# STM32F303CBT6 register map
File version: 1.0
Registers are 32-bit, access not given, reset 0x0 unless marked. A register's access mark holds for its fields unless they carry their own. Offsets are from the block's base; [hi:lo] are bit positions; {n}, {i} and the like mark numbered series; 'fields as' and 'values as' point back to an identical list.

## TIM15
Base 0x40014000
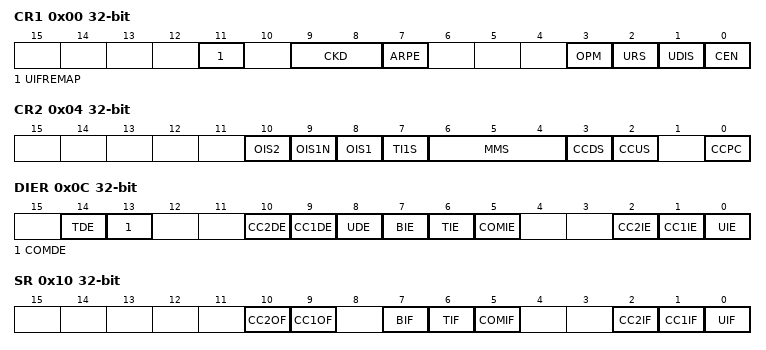
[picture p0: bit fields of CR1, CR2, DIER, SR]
0x00 CR1
  [11] UIFREMAP, [9:8] CKD, [7] ARPE, [3] OPM, [2] URS, [1] UDIS, [0] CEN
0x04 CR2
  [10] OIS2, [9] OIS1N, [8] OIS1, [7] TI1S, [6:4] MMS, [3] CCDS, [2] CCUS, [0] CCPC
0x08 SMCR
  [7] MSM, [6:4] TS, [16:0] SMS
0x0C DIER
  [14] TDE, [13] COMDE, [10] CC2DE, [9] CC1DE, [8] UDE, [7] BIE, [6] TIE, [5] COMIE, [2] CC2IE, [1] CC1IE, [0] UIE
0x10 SR
  [10] CC2OF, [9] CC1OF, [7] BIF, [6] TIF, [5] COMIF, [2] CC2IF, [1] CC1IF, [0] UIF
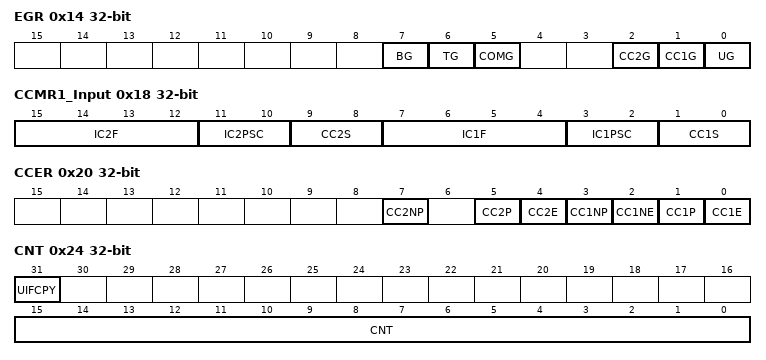
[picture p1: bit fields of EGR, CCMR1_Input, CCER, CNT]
0x14 EGR
  [7] BG, [6] TG, [5] COMG, [2] CC2G, [1] CC1G, [0] UG
0x18 CCMR1_Output
  [24:12] OC2M, [11] OC2PE, [10] OC2FE, [9:8] CC2S, [7] OC1CE, [16:4] OC1M, [3] OC1PE, [2] OC1FE, [1:0] CC1S
0x18 CCMR1_Input
  [15:12] IC2F, [11:10] IC2PSC, [9:8] CC2S, [7:4] IC1F, [3:2] IC1PSC, [1:0] CC1S
0x20 CCER
  [7] CC2NP, [5] CC2P, [4] CC2E, [3] CC1NP, [2] CC1NE, [1] CC1P, [0] CC1E
0x24 CNT
  [31] UIFCPY, [15:0] CNT
0x28 PSC
  [15:0] PSC
0x2C ARR
  [15:0] ARR
0x30 RCR
  [7:0] REP
0x34 CCR1
  [15:0] CCR1
0x38 CCR2
  [15:0] CCR2
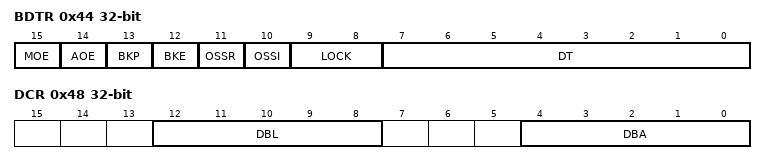
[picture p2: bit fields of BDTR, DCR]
0x44 BDTR
  [15] MOE, [14] AOE, [13] BKP, [12] BKE, [11] OSSR, [10] OSSI, [9:8] LOCK, [7:0] DT
0x48 DCR
  [12:8] DBL, [4:0] DBA
0x4C DMAR
  [15:0] DMAB

## TIM16
Base 0x40014400
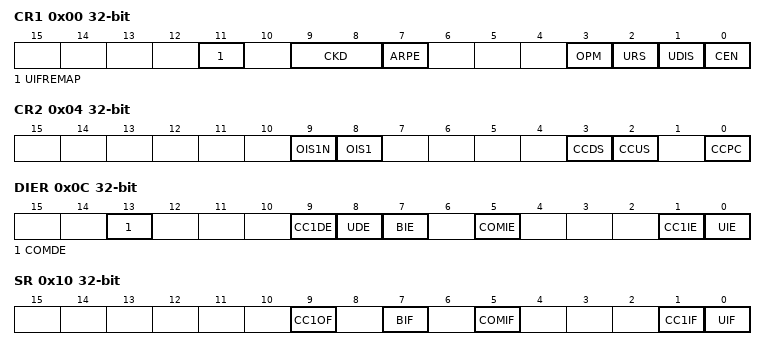
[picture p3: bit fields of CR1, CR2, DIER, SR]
0x00 CR1
  [11] UIFREMAP, [9:8] CKD, [7] ARPE, [3] OPM, [2] URS, [1] UDIS, [0] CEN
0x04 CR2
  [9] OIS1N, [8] OIS1, [3] CCDS, [2] CCUS, [0] CCPC
0x0C DIER
  [13] COMDE, [9] CC1DE, [8] UDE, [7] BIE, [5] COMIE, [1] CC1IE, [0] UIE
0x10 SR
  [9] CC1OF, [7] BIF, [5] COMIF, [1] CC1IF, [0] UIF
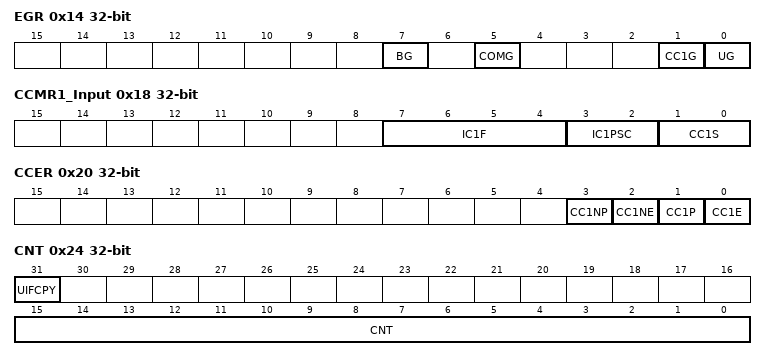
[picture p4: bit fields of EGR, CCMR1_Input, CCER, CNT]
0x14 EGR
  [7] BG, [5] COMG, [1] CC1G, [0] UG
0x18 CCMR1_Output
  [7] OC1CE, [16:4] OC1M, [3] OC1PE, [2] OC1FE, [1:0] CC1S
0x18 CCMR1_Input
  [7:4] IC1F, [3:2] IC1PSC, [1:0] CC1S
0x20 CCER
  [3] CC1NP, [2] CC1NE, [1] CC1P, [0] CC1E
0x24 CNT
  [31] UIFCPY, [15:0] CNT
0x28 PSC
  [15:0] PSC
0x2C ARR
  [15:0] ARR
0x30 RCR
  [7:0] REP
0x34 CCR1
  [15:0] CCR1
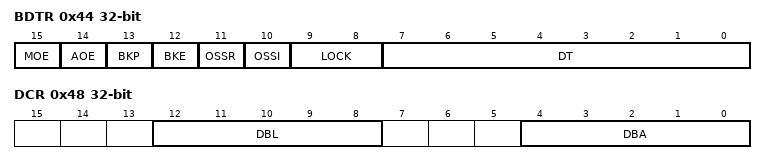
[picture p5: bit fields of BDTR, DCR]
0x44 BDTR
  [15] MOE, [14] AOE, [13] BKP, [12] BKE, [11] OSSR, [10] OSSI, [9:8] LOCK, [7:0] DT
0x48 DCR
  [12:8] DBL, [4:0] DBA
0x4C DMAR
  [15:0] DMAB
0x50 OR
  [1:0] TI1_RMP

## TIM17
Base 0x40014800
Registers as TIM16, without OR.

## DMA1
Base 0x40020000
Same registers: DMA2 0x40020400
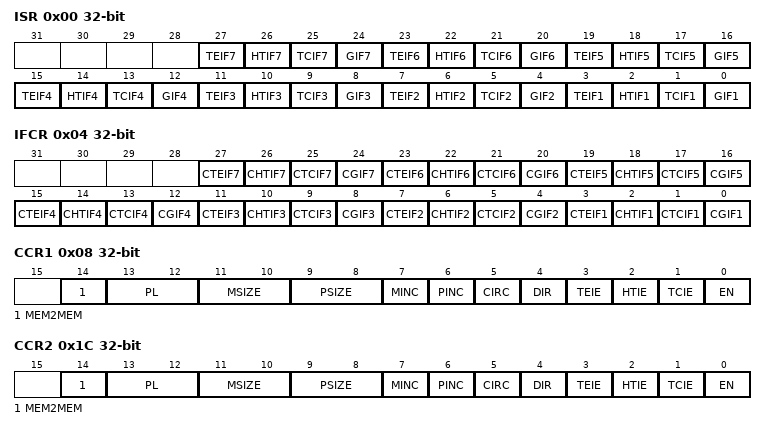
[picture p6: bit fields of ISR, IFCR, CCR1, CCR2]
0x00 ISR
  [4n-1] TEIF{n} (n=1..7), [4n-2] HTIF{n} (n=1..7), [4n-3] TCIF{n} (n=1..7), [4n-4] GIF{n} (n=1..7)
0x04 IFCR
  [4n-1] CTEIF{n} (n=1..7), [4n-2] CHTIF{n} (n=1..7), [4n-3] CTCIF{n} (n=1..7), [4n-4] CGIF{n} (n=1..7)
0x08 CCR1
  [14] MEM2MEM, [13:12] PL, [11:10] MSIZE, [9:8] PSIZE, [7] MINC, [6] PINC, [5] CIRC, [4] DIR, [3] TEIE, [2] HTIE, [1] TCIE, [0] EN
0x0C CNDTR1
  [15:0] NDT
0x10 CPAR1
  [31:0] PA
{0x0+0x14*i} CMAR{i} (i=1..7)
  [31:0] MA
0x1C CCR2
  fields as CCR1
0x20 CNDTR2
  [15:0] NDT
0x24 CPAR2
  [31:0] PA
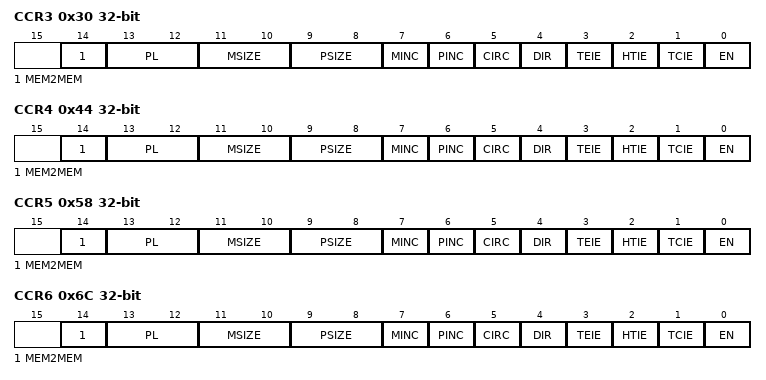
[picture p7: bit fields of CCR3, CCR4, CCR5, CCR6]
0x30 CCR3
  fields as CCR1
0x34 CNDTR3
  [15:0] NDT
0x38 CPAR3
  [31:0] PA
0x44 CCR4
  fields as CCR1
0x48 CNDTR4
  [15:0] NDT
0x4C CPAR4
  [31:0] PA
0x58 CCR5
  fields as CCR1
0x5C CNDTR5
  [15:0] NDT
0x60 CPAR5
  [31:0] PA
0x6C CCR6
  fields as CCR1
0x70 CNDTR6
  [15:0] NDT
0x74 CPAR6
  [31:0] PA
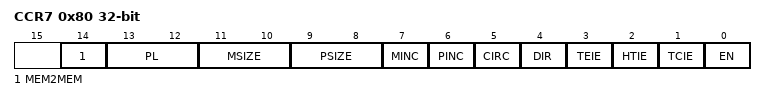
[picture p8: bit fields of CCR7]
0x80 CCR7
  fields as CCR1
0x84 CNDTR7
  [15:0] NDT
0x88 CPAR7
  [31:0] PA

## RCC
Base 0x40021000
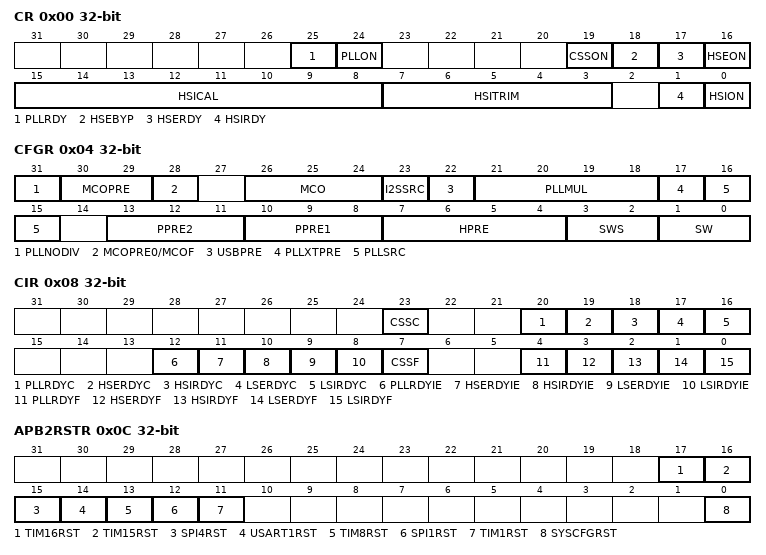
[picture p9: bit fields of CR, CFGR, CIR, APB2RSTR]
0x00 CR
  [25] PLLRDY, [24] PLLON, [19] CSSON, [18] HSEBYP, [17] HSERDY, [16] HSEON, [15:8] HSICAL, [7:3] HSITRIM, [1] HSIRDY, [0] HSION
0x04 CFGR
  [31] PLLNODIV, [30:29] MCOPRE, [28] MCOPRE0/MCOF, [26:24] MCO, [23] I2SSRC, [22] USBPRE, [21:18] PLLMUL, [17] PLLXTPRE, [16:15] PLLSRC, [13:11] PPRE2, [10:8] PPRE1, [7:4] HPRE, [3:2] SWS, [1:0] SW
0x08 CIR
  [23] CSSC, [20] PLLRDYC, [19] HSERDYC, [18] HSIRDYC, [17] LSERDYC, [16] LSIRDYC, [12] PLLRDYIE, [11] HSERDYIE, [10] HSIRDYIE, [9] LSERDYIE, [8] LSIRDYIE, [7] CSSF, [4] PLLRDYF, [3] HSERDYF, [2] HSIRDYF, [1] LSERDYF, [0] LSIRDYF
0x0C APB2RSTR
  [17] TIM16RST, [16] TIM15RST, [15] SPI4RST, [14] USART1RST, [13] TIM8RST, [12] SPI1RST, [11] TIM1RST, [0] SYSCFGRST
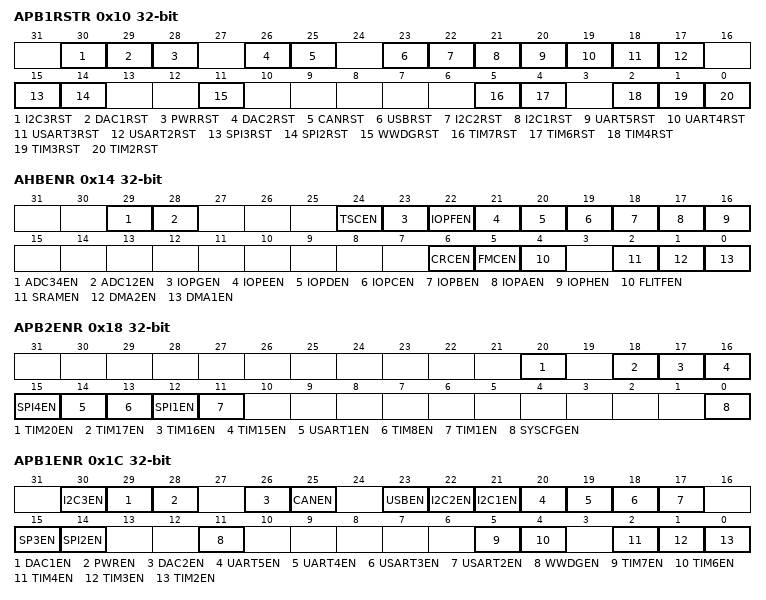
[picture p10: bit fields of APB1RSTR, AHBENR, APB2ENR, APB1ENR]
0x10 APB1RSTR
  [30] I2C3RST, [29] DAC1RST, [28] PWRRST, [26] DAC2RST, [25] CANRST, [23] USBRST, [22] I2C2RST, [21] I2C1RST, [20] UART5RST, [19] UART4RST, [18] USART3RST, [17] USART2RST, [15] SPI3RST, [14] SPI2RST, [11] WWDGRST, [5] TIM7RST, [4] TIM6RST, [2] TIM4RST, [1] TIM3RST, [0] TIM2RST
0x14 AHBENR
  [29] ADC34EN, [28] ADC12EN, [24] TSCEN, [23] IOPGEN, [22] IOPFEN, [21] IOPEEN, [20] IOPDEN, [19] IOPCEN, [18] IOPBEN, [17] IOPAEN, [16] IOPHEN, [6] CRCEN, [5] FMCEN, [4] FLITFEN, [2] SRAMEN, [1] DMA2EN, [0] DMA1EN
0x18 APB2ENR
  [20] TIM20EN, [18] TIM17EN, [17] TIM16EN, [16] TIM15EN, [15] SPI4EN, [14] USART1EN, [13] TIM8EN, [12] SPI1EN, [11] TIM1EN, [0] SYSCFGEN
0x1C APB1ENR
  [30] I2C3EN, [29] DAC1EN, [28] PWREN, [26] DAC2EN, [25] CANEN, [23] USBEN, [22] I2C2EN, [21] I2C1EN, [20] UART5EN, [19] UART4EN, [18] USART3EN, [17] USART2EN, [15] SP3EN, [14] SPI2EN, [11] WWDGEN, [5] TIM7EN, [4] TIM6EN, [2] TIM4EN, [1] TIM3EN, [0] TIM2EN
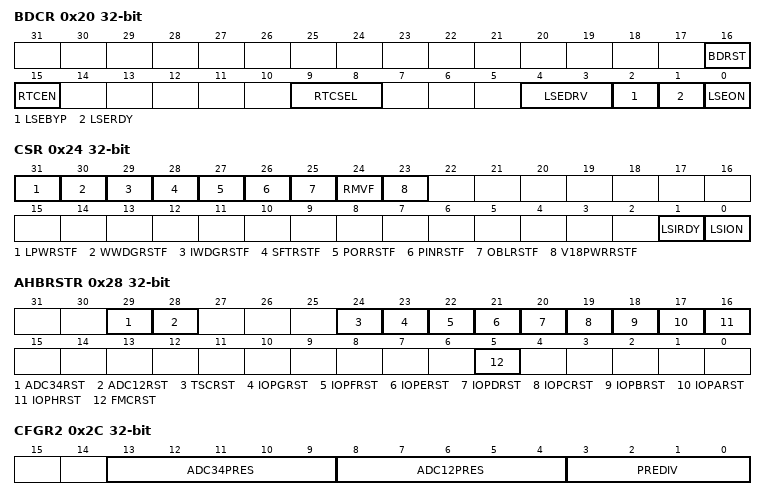
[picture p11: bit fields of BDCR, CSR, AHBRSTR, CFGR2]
0x20 BDCR
  [16] BDRST, [15] RTCEN, [9:8] RTCSEL, [4:3] LSEDRV, [2] LSEBYP, [1] LSERDY, [0] LSEON
0x24 CSR
  [31] LPWRSTF, [30] WWDGRSTF, [29] IWDGRSTF, [28] SFTRSTF, [27] PORRSTF, [26] PINRSTF, [25] OBLRSTF, [24] RMVF, [23] V18PWRRSTF, [1] LSIRDY, [0] LSION
0x28 AHBRSTR
  [29] ADC34RST, [28] ADC12RST, [24] TSCRST, [23] IOPGRST, [22] IOPFRST, [21] IOPERST, [20] IOPDRST, [19] IOPCRST, [18] IOPBRST, [17] IOPARST, [16] IOPHRST, [5] FMCRST
0x2C CFGR2
  [13:9] ADC34PRES, [8:4] ADC12PRES, [3:0] PREDIV
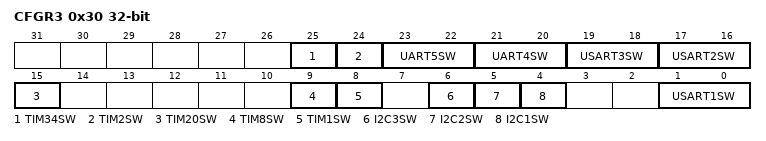
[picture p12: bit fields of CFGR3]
0x30 CFGR3
  [25] TIM34SW, [24] TIM2SW, [23:22] UART5SW, [21:20] UART4SW, [19:18] USART3SW, [17:16] USART2SW, [15] TIM20SW, [9] TIM8SW, [8] TIM1SW, [6] I2C3SW, [5] I2C2SW, [4] I2C1SW, [1:0] USART1SW

## FLASH
Base 0x40022000
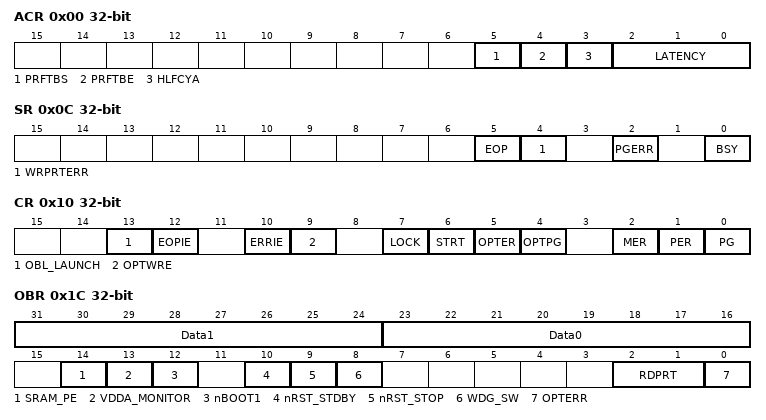
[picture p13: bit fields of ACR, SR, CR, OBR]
0x00 ACR
  [5] PRFTBS, [4] PRFTBE, [3] HLFCYA, [2:0] LATENCY
0x04 KEYR
  [31:0] FKEYR
0x08 OPTKEYR
0x0C SR
  [5] EOP, [4] WRPRTERR, [2] PGERR, [0] BSY
0x10 CR
  [13] OBL_LAUNCH, [12] EOPIE, [10] ERRIE, [9] OPTWRE, [7] LOCK, [6] STRT, [5] OPTER, [4] OPTPG, [2] MER, [1] PER, [0] PG
0x14 AR
  [31:0] FAR
0x1C OBR
  [31:24] Data1, [23:16] Data0, [14] SRAM_PE, [13] VDDA_MONITOR, [12] nBOOT1, [10] nRST_STDBY, [9] nRST_STOP, [8] WDG_SW, [2:1] RDPRT, [0] OPTERR
0x20 WRPR
  [31:0] WRP

## CRC
Base 0x40023000
0x00 DR
0x04 IDR
  [7:0] IDR
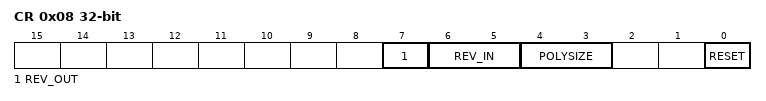
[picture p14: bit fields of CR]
0x08 CR
  [7] REV_OUT, [6:5] REV_IN, [4:3] POLYSIZE, [0] RESET
0x10 INIT
  [31:0] CRC_INIT
0x14 POL
  [31:0] Polynomialcoefficients

## TSC
Base 0x40024000
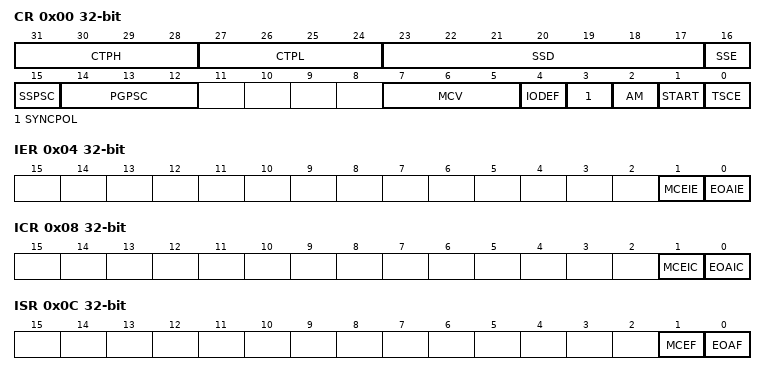
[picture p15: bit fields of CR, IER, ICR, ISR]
0x00 CR
  [31:28] CTPH, [27:24] CTPL, [23:17] SSD, [16] SSE, [15] SSPSC, [14:12] PGPSC, [7:5] MCV, [4] IODEF, [3] SYNCPOL, [2] AM, [1] START, [0] TSCE
0x04 IER
  [1] MCEIE, [0] EOAIE
0x08 ICR
  [1] MCEIC, [0] EOAIC
0x0C ISR
  [1] MCEF, [0] EOAF
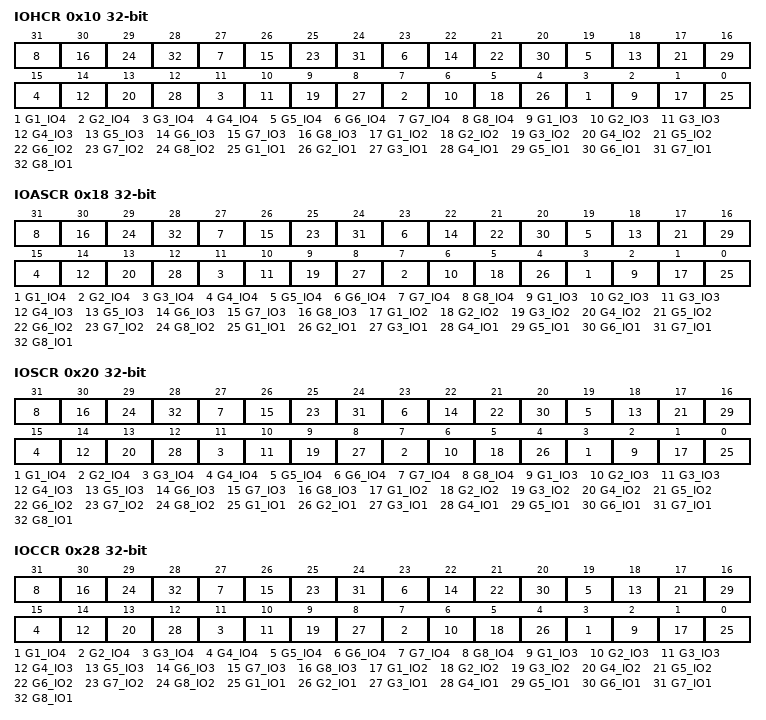
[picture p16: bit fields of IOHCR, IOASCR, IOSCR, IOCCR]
0x10 IOHCR
  [4n-1] G{n}_IO4 (n=1..8), [4n-2] G{n}_IO3 (n=1..8), [4n-3] G{n}_IO2 (n=1..8), [4n-4] G{n}_IO1 (n=1..8)
0x18 IOASCR
  fields as IOHCR
0x20 IOSCR
  fields as IOHCR
0x28 IOCCR
  fields as IOHCR
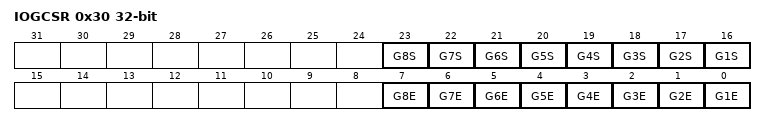
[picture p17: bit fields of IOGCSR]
0x30 IOGCSR
  [n+15] G{n}S (n=1..8), [n-1] G{n}E (n=1..8)
{0x30+4i} IOG{i}CR (i=1..8)
  [13:0] CNT

## GPIOA
Base 0x48000000
Same registers: GPIOB 0x48000400, GPIOC 0x48000800, GPIOD 0x48000C00, GPIOE 0x48001000, GPIOF 0x48001400
0x00 MODER
  [2n+1:2n] MODER{n} (n=0..15)
0x04 OTYPER
  [n] OT{n} (n=0..15)
0x08 OSPEEDR
  [2n+1:2n] OSPEEDR{n} (n=0..15)
0x0C PUPDR
  [2n+1:2n] PUPDR{n} (n=0..15)
0x10 IDR
  [n] IDR{n} (n=0..15)
0x14 ODR
  [n] ODR{n} (n=0..15)
0x18 BSRR
  [n+16] BR{n} (n=0..15), [n] BS{n} (n=0..15)
0x1C LCKR)
  [16] LCKK, [n] LCK{n} (n=0..15)
0x20 AFRL
  [4n+3:4n] AFRLAFR{n} (n=0..7)
0x24 AFRH
  [4n-29:4n-32] AFRHAFR{n} (n=8..15)
0x28 BRR
  [n] BR{n} (n=0..15)

## ADC1
Base 0x50000000
Same registers: ADC2 0x50000100, ADC3 0x50000400, ADC4 0x50000500
0x00 ISR
  [10] JQOVF, [9] AWD3, [8] AWD2, [7] AWD1, [6] JEOS, [5] JEOC, [4] OVR, [3] EOS, [2] EOC, [1] EOSMP, [0] ADRDY
0x04 IER
  [10] JQOVFIE, [9] AWD3IE, [8] AWD2IE, [7] AWD1IE, [6] JEOSIE, [5] JEOCIE, [4] OVRIE, [3] EOSIE, [2] EOCIE, [1] EOSMPIE, [0] ADRDYIE
0x08 CR
  [31] ADCAL, [30] ADCALDIF, [29:28] ADVREGEN, [5] JADSTP, [4] ADSTP, [3] JADSTART, [2] ADSTART, [1] ADDIS, [0] ADEN
0x0C CFGR
  [30:26] AWD1CH, [25] JAUTO, [24] JAWD1EN, [23] AWD1EN, [22] AWD1SGL, [21] JQM, [20] JDISCEN, [19:17] DISCNUM, [16] DISCEN, [14] AUTDLY, [13] CONT, [12] OVRMOD, [11:10] EXTEN, [9:6] EXTSEL, [5] ALIGN, [4:3] RES, [1] DMACFG, [0] DMAEN
0x14 SMPR1
  [3n+2:3n] SMP{n} (n=1..9)
0x18 SMPR2
  [3n-28:3n-30] SMP{n} (n=10..18)
0x20 TR1
  [27:16] HT1, [11:0] LT1
0x24 TR2
  [23:16] HT2, [7:0] LT2
0x28 TR3
  [23:16] HT3, [7:0] LT3
0x30 SQR1
  [6n+4:6n] SQ{n} (n=1..4), [3:0] L
0x34 SQR2
  [6n-26:6n-30] SQ{n} (n=5..9)
0x38 SQR3
  [6n-56:6n-60] SQ{n} (n=10..14)
0x3C SQR4
  [10:6] SQ16, [4:0] SQ15
0x40 DR
  [15:0] RDATA
0x4C JSQR
  [6n+6:6n+2] JSQ{n} (n=1..4), [7:6] JEXTEN, [5:2] JEXTSEL, [1:0] JL
{0x5C+4i} OFR{i} (i=1..4)
  [31] OFFSET{i}_EN, [30:26] OFFSET{i}_CH, [11:0] OFFSET{i}
{0x7C+4i} JDR{i} (i=1..4)
  [15:0] JDATA{i}
0xA0 AWD2CR
  [18:1] AWD2CH
0xA4 AWD3CR
  [18:1] AWD3CH
0xB0 DIFSEL
  [18:1] DIFSEL
0xB4 CALFACT
  [22:16] CALFACT_D, [6:0] CALFACT_S
